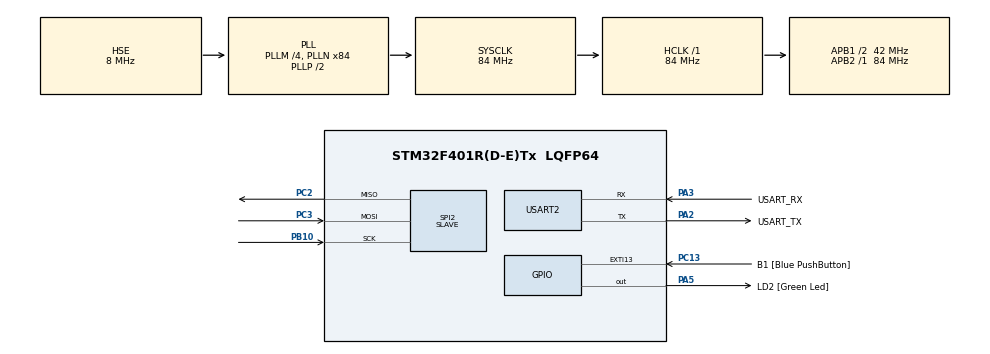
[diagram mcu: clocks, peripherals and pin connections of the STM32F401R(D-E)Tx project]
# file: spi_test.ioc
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Mcu.Family=STM32F4
PC3.Mode=Full_Duplex_Slave
RCC.PLLSourceVirtual=RCC_PLLSOURCE_HSE
PC15-OSC32_OUT.Mode=LSE-External-Oscillator
PA2.GPIO_PuPd=GPIO_NOPULL
RCC.CortexFreq_Value=84000000
PC13-ANTI_TAMP.GPIO_PuPd=GPIO_NOPULL
SPI2.VirtualType=VM_SLAVE
PB10.Mode=Full_Duplex_Slave
PC13-ANTI_TAMP.GPIO_Label=B1 [Blue PushButton]
PA14.GPIO_Label=TCK
PA3.GPIO_PuPd=GPIO_NOPULL
PH1\ -\ OSC_OUT.Mode=HSE-External-Clock-Source
PC2.Signal=SPI2_MISO
PA2.GPIO_Speed=GPIO_SPEED_FREQ_LOW
PC2.Mode=Full_Duplex_Slave
RCC.APB1CLKDivider=RCC_HCLK_DIV2
PC14-OSC32_IN.Signal=RCC_OSC32_IN
PA3.GPIO_Speed=GPIO_SPEED_FREQ_LOW
RCC.SYSCLKSource=RCC_SYSCLKSOURCE_PLLCLK
ProjectManager.StackSize=0x400
PA13.Signal=SYS_JTMS-SWDIO
PA3.Mode=Asynchronous
PH0\ -\ OSC_IN.Mode=HSE-External-Clock-Source
PH0\ -\ OSC_IN.Signal=RCC_OSC_IN
ProjectManager.TargetToolchain=TrueSTUDIO
PA3.GPIO_Mode=GPIO_MODE_AF_PP
RCC.HCLKFreq_Value=84000000
RCC.APB2TimFreq_Value=84000000
PC3.Signal=SPI2_MOSI
PC15-OSC32_OUT.Signal=RCC_OSC32_OUT
RCC.AHBFreq_Value=84000000
PB10.Signal=SPI2_SCK
PA5.Signal=GPIO_Output
RCC.HSE_VALUE=8000000
PH1\ -\ OSC_OUT.Signal=RCC_OSC_OUT
board=NUCLEO-F401RE
PC13-ANTI_TAMP.Signal=GPXTI13
RCC.VCOOutputFreq_Value=168000000
RCC.APB2Freq_Value=84000000
PC14-OSC32_IN.Mode=LSE-External-Oscillator
PA14.Mode=Serial_Wire
PA5.GPIO_PuPd=GPIO_NOPULL
PA13.Mode=Serial_Wire
Mcu.Name=STM32F401R(D-E)Tx
PA2.Signal=USART2_TX
PA13.GPIO_Label=TMS
RCC.48MHZClocksFreq_Value=24000000
PB3.Signal=SYS_JTDO-SWO
RCC.SYSCLKFreq_VALUE=84000000
Mcu.Package=LQFP64
SPI2.Mode=SPI_MODE_SLAVE
PA5.GPIO_Label=LD2 [Green Led]
USART2.VirtualMode=VM_ASYNC
PC13-ANTI_TAMP.GPIO_ModeDefaultEXTI=GPIO_MODE_IT_FALLING
PA2.GPIO_Label=USART_TX
PA14.Signal=SYS_JTCK-SWCLK
ProjectManager.HeapSize=0x200
RCC.HSI_VALUE=16000000
PA5.GPIO_Speed=GPIO_SPEED_FREQ_LOW
RCC.PLLQ=7
NVIC.PriorityGroup=NVIC_PRIORITYGROUP_0
RCC.PLLM=4
RCC.PLLN=84
RCC.APB1TimFreq_Value=84000000
PA2.Mode=Asynchronous
SPI2.Direction=SPI_DIRECTION_2LINES
RCC.APB1Freq_Value=42000000
PA5.GPIO_Mode=GPIO_MODE_OUTPUT_PP
PA3.GPIO_Label=USART_RX
PA3.Signal=USART2_RX
PA2.GPIO_Mode=GPIO_MODE_AF_PP
PB3.GPIO_Label=SWO

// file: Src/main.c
/* USER CODE BEGIN Header */
/**
  ******************************************************************************
  * @file           : main.c
  * @brief          : Main program body
  ******************************************************************************
  * @attention
  *
  * <h2><center>&copy; Copyright (c) 2020 STMicroelectronics.
  * All rights reserved.</center></h2>
  *
  * This software component is licensed by ST under BSD 3-Clause license,
  * the "License"; You may not use this file except in compliance with the
  * License. You may obtain a copy of the License at:
  *                        opensource.org/licenses/BSD-3-Clause
  *
  ******************************************************************************
  */
/* USER CODE END Header */

#include "main.h"
#include "stdio.h"
#include "stdint.h"
#include "string.h"

/* USER CODE BEGIN PM */
/* Private function prototypes -----------------------------------------------*/

/* USER CODE END PM */

SPI_HandleTypeDef hspi2;

UART_HandleTypeDef huart2;

void SystemClock_Config(void);
static void MX_GPIO_Init(void);
static void MX_SPI2_Init(void);
static void MX_USART2_UART_Init(void);

/* USER CODE BEGIN 0 */
#ifdef __GNUC__
  /* With GCC, small printf (option LD Linker->Libraries->Small printf
     set to 'Yes') calls __io_putchar() */
  #define PUTCHAR_PROTOTYPE int __io_putchar(int ch)
#else
  #define PUTCHAR_PROTOTYPE int fputc(int ch, FILE *f)
#endif /* __GNUC__ */
/**
  * @brief  Retargets the C library printf function to the USART.
  * @param  None
  * @retval None
  */
PUTCHAR_PROTOTYPE
{
  /* Place your implementation of fputc here */
  /* e.g. write a character to the EVAL_COM1 and Loop until the end of transmission */
  HAL_UART_Transmit(&huart2, (uint8_t *)&ch, 1, 0xFFFF);

  return ch;
}

/* USER CODE END 0 */

int main(void)
{
  /* USER CODE BEGIN 1 */
char g[1000];
  /* USER CODE END 1 */

  /* MCU Configuration--------------------------------------------------------*/

  /* Reset of all peripherals, Initializes the Flash interface and the Systick. */
  HAL_Init();

  /* Configure the system clock */
  SystemClock_Config();

  /* Initialize all configured peripherals */
  MX_GPIO_Init();
  MX_SPI2_Init();
  MX_USART2_UART_Init();

  /* Infinite loop */
  /* USER CODE BEGIN WHILE */
  while (1)
  {
	  sprintf(g,"hello world \n");
	 printf("hello world from printf");
	  HAL_UART_Transmit(&huart2,(uint8_t*)g,strlen(g),1000)
;	  HAL_Delay(1000);
    /* USER CODE END WHILE */

  }
}

void SystemClock_Config(void)
{
  RCC_OscInitTypeDef RCC_OscInitStruct = {0};
  RCC_ClkInitTypeDef RCC_ClkInitStruct = {0};

  /** Configure the main internal regulator output voltage
  */
  __HAL_RCC_PWR_CLK_ENABLE();
  __HAL_PWR_VOLTAGESCALING_CONFIG(PWR_REGULATOR_VOLTAGE_SCALE2);
  /** Initializes the CPU, AHB and APB busses clocks
  */
  RCC_OscInitStruct.OscillatorType = RCC_OSCILLATORTYPE_HSE;
  RCC_OscInitStruct.HSEState = RCC_HSE_BYPASS;
  RCC_OscInitStruct.PLL.PLLState = RCC_PLL_ON;
  RCC_OscInitStruct.PLL.PLLSource = RCC_PLLSOURCE_HSE;
  RCC_OscInitStruct.PLL.PLLM = 4;
  RCC_OscInitStruct.PLL.PLLN = 84;
  RCC_OscInitStruct.PLL.PLLP = RCC_PLLP_DIV2;
  RCC_OscInitStruct.PLL.PLLQ = 7;
  if (HAL_RCC_OscConfig(&RCC_OscInitStruct) != HAL_OK)
  {
    Error_Handler();
  }
  /** Initializes the CPU, AHB and APB busses clocks
  */
  RCC_ClkInitStruct.ClockType = RCC_CLOCKTYPE_HCLK|RCC_CLOCKTYPE_SYSCLK
                              |RCC_CLOCKTYPE_PCLK1|RCC_CLOCKTYPE_PCLK2;
  RCC_ClkInitStruct.SYSCLKSource = RCC_SYSCLKSOURCE_PLLCLK;
  RCC_ClkInitStruct.AHBCLKDivider = RCC_SYSCLK_DIV1;
  RCC_ClkInitStruct.APB1CLKDivider = RCC_HCLK_DIV2;
  RCC_ClkInitStruct.APB2CLKDivider = RCC_HCLK_DIV1;

  if (HAL_RCC_ClockConfig(&RCC_ClkInitStruct, FLASH_LATENCY_2) != HAL_OK)
  {
    Error_Handler();
  }
}

static void MX_SPI2_Init(void)
{

  /* SPI2 parameter configuration*/
  hspi2.Instance = SPI2;
  hspi2.Init.Mode = SPI_MODE_SLAVE;
  hspi2.Init.Direction = SPI_DIRECTION_2LINES;
  hspi2.Init.DataSize = SPI_DATASIZE_8BIT;
  hspi2.Init.CLKPolarity = SPI_POLARITY_LOW;
  hspi2.Init.CLKPhase = SPI_PHASE_1EDGE;
  hspi2.Init.NSS = SPI_NSS_SOFT;
  hspi2.Init.FirstBit = SPI_FIRSTBIT_MSB;
  hspi2.Init.TIMode = SPI_TIMODE_DISABLE;
  hspi2.Init.CRCCalculation = SPI_CRCCALCULATION_DISABLE;
  hspi2.Init.CRCPolynomial = 10;
  if (HAL_SPI_Init(&hspi2) != HAL_OK)
  {
    Error_Handler();
  }

}

static void MX_USART2_UART_Init(void)
{

  huart2.Instance = USART2;
  huart2.Init.BaudRate = 115200;
  huart2.Init.WordLength = UART_WORDLENGTH_8B;
  huart2.Init.StopBits = UART_STOPBITS_1;
  huart2.Init.Parity = UART_PARITY_NONE;
  huart2.Init.Mode = UART_MODE_TX_RX;
  huart2.Init.HwFlowCtl = UART_HWCONTROL_NONE;
  huart2.Init.OverSampling = UART_OVERSAMPLING_16;
  if (HAL_UART_Init(&huart2) != HAL_OK)
  {
    Error_Handler();
  }

}

static void MX_GPIO_Init(void)
{
  GPIO_InitTypeDef GPIO_InitStruct = {0};

  /* GPIO Ports Clock Enable */
  __HAL_RCC_GPIOC_CLK_ENABLE();
  __HAL_RCC_GPIOH_CLK_ENABLE();
  __HAL_RCC_GPIOA_CLK_ENABLE();
  __HAL_RCC_GPIOB_CLK_ENABLE();

  /*Configure GPIO pin Output Level */
  HAL_GPIO_WritePin(LD2_GPIO_Port, LD2_Pin, GPIO_PIN_RESET);

  /*Configure GPIO pin : B1_Pin */
  GPIO_InitStruct.Pin = B1_Pin;
  GPIO_InitStruct.Mode = GPIO_MODE_IT_FALLING;
  GPIO_InitStruct.Pull = GPIO_NOPULL;
  HAL_GPIO_Init(B1_GPIO_Port, &GPIO_InitStruct);

  /*Configure GPIO pin : LD2_Pin */
  GPIO_InitStruct.Pin = LD2_Pin;
  GPIO_InitStruct.Mode = GPIO_MODE_OUTPUT_PP;
  GPIO_InitStruct.Pull = GPIO_NOPULL;
  GPIO_InitStruct.Speed = GPIO_SPEED_FREQ_LOW;
  HAL_GPIO_Init(LD2_GPIO_Port, &GPIO_InitStruct);

}

void Error_Handler(void)
{
}

/************************ (C) COPYRIGHT STMicroelectronics *****END OF FILE****/
